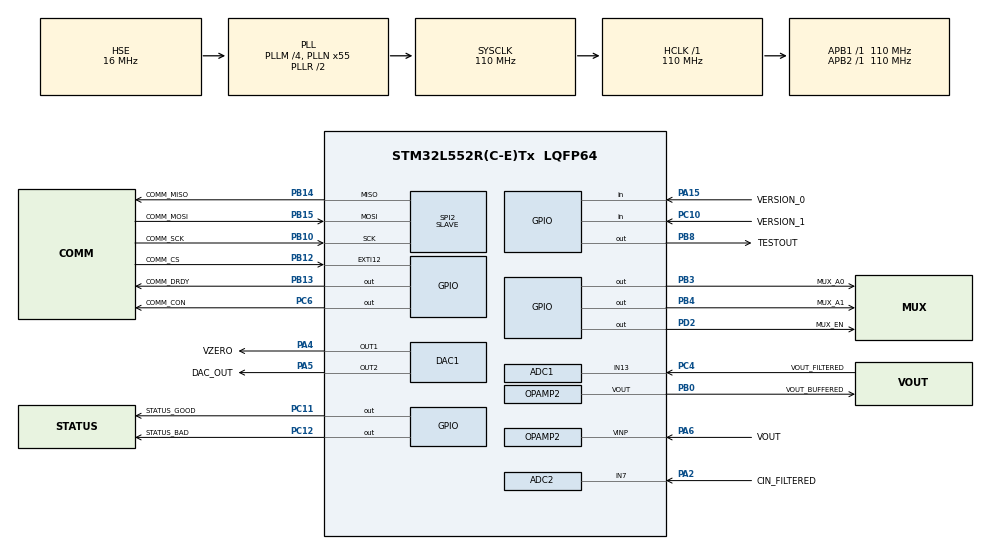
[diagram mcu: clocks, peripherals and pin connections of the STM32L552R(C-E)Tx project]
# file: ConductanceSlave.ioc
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ADC1.Channel-2\#ChannelRegularConversion=ADC_CHANNEL_13
ADC1.ClockPrescaler=ADC_CLOCK_SYNC_PCLK_DIV2
ADC1.ExternalTrigConv=ADC_EXTERNALTRIG_T1_TRGO
ADC1.NbrOfConversion=1
ADC1.NbrOfConversionFlag=1
ADC1.OffsetNumber-2\#ChannelRegularConversion=ADC_OFFSET_NONE
ADC1.OversamplingMode=ENABLE
ADC1.Rank-2\#ChannelRegularConversion=1
ADC1.Ratio=ADC_OVERSAMPLING_RATIO_256
ADC1.RightBitShift=ADC_RIGHTBITSHIFT_4
ADC1.SamplingTime-2\#ChannelRegularConversion=ADC_SAMPLETIME_6CYCLES_5
ADC1.master=1
ADC2.Channel-4\#ChannelRegularConversion=ADC_CHANNEL_7
ADC2.ClockPrescaler=ADC_CLOCK_SYNC_PCLK_DIV2
ADC2.ExternalTrigConv=ADC_EXTERNALTRIG_T1_TRGO
ADC2.NbrOfConversionFlag=1
ADC2.OffsetNumber-4\#ChannelRegularConversion=ADC_OFFSET_NONE
ADC2.OversamplingMode=ENABLE
ADC2.Rank-4\#ChannelRegularConversion=1
ADC2.Ratio=ADC_OVERSAMPLING_RATIO_256
ADC2.RightBitShift=ADC_RIGHTBITSHIFT_4
ADC2.SamplingTime-4\#ChannelRegularConversion=ADC_SAMPLETIME_6CYCLES_5
DAC1.DAC_Channel-DAC_OUT2=DAC_CHANNEL_2
DAC1.DAC_OutputBuffer-DAC_OUT1=DAC_OUTPUTBUFFER_DISABLE
DAC1.DAC_Trigger-DAC_OUT1=DAC_TRIGGER_NONE
Dma.Request0=SPI2_RX
Dma.SPI2_RX.0.Channel_PRIV_NPRIV=DMA_CHANNEL_NPRIV_DISABLE
Dma.SPI2_RX.0.Direction=DMA_PERIPH_TO_MEMORY
Dma.SPI2_RX.0.EventEnable=DISABLE
Dma.SPI2_RX.0.Instance=DMA2_Channel1
Dma.SPI2_RX.0.MemDataAlignment=DMA_MDATAALIGN_HALFWORD
Dma.SPI2_RX.0.MemInc=DMA_MINC_ENABLE
Dma.SPI2_RX.0.Mode=DMA_NORMAL
Dma.SPI2_RX.0.PeriphDataAlignment=DMA_PDATAALIGN_HALFWORD
Dma.SPI2_RX.0.PeriphInc=DMA_PINC_DISABLE
Dma.SPI2_RX.0.Polarity=HAL_DMAMUX_REQ_GEN_RISING
Dma.SPI2_RX.0.Priority=DMA_PRIORITY_HIGH
Dma.SPI2_RX.0.RequestNumber=1
Dma.SPI2_RX.0.SignalID=NONE
Dma.SPI2_RX.0.SyncEnable=DISABLE
Dma.SPI2_RX.0.SyncPolarity=HAL_DMAMUX_SYNC_NO_EVENT
Dma.SPI2_RX.0.SyncRequestNumber=1
Dma.SPI2_RX.0.SyncSignalID=NONE
Mcu.Family=STM32L5
Mcu.Name=STM32L552R(C-E)Tx
Mcu.Package=LQFP64
NVIC.DMA2_Channel1_IRQn=true\:0\:0\:false\:false\:true\:false\:true\:true
NVIC.EXTI12_IRQn=true\:1\:0\:true\:false\:true\:true\:true\:true
NVIC.PriorityGroup=NVIC_PRIORITYGROUP_3
OPAMP2.PowerSupplyRange=OPAMP_POWERSUPPLY_HIGH
PA13\ (JTMS/SWDIO).Mode=Serial_Wire
PA13\ (JTMS/SWDIO).Signal=DEBUG_JTMS-SWDIO
PA14\ (JTCK/SWCLK).Mode=Serial_Wire
PA14\ (JTCK/SWCLK).Signal=DEBUG_JTCK-SWCLK
PA15\ (JTDI).GPIO_Label=VERSION_0
PA15\ (JTDI).GPIO_PuPd=GPIO_PULLDOWN
PA15\ (JTDI).Signal=GPIO_Input
PA2.GPIO_Label=CIN_FILTERED
PA2.Signal=ADCx_IN7
PA4.GPIO_Label=VZERO
PA4.Signal=COMP_DAC11_group
PA5.GPIO_Label=DAC_OUT
PA5.Signal=COMP_DAC12_group
PA6.GPIO_Label=VOUT
PA6.Mode=Follower
PA6.Signal=OPAMP2_VINP
PB0.GPIO_Label=VOUT_BUFFERED
PB0.Mode=Follower
PB0.Signal=OPAMP2_VOUT
PB10.GPIO_Label=COMM_SCK
PB10.GPIO_Speed=GPIO_SPEED_FREQ_VERY_HIGH
PB10.Mode=Full_Duplex_Slave
PB10.Signal=SPI2_SCK
PB12.GPIO_Label=COMM_CS
PB12.GPIO_ModeDefaultEXTI=GPIO_MODE_IT_RISING_FALLING
PB12.GPIO_PuPd=GPIO_PULLUP
PB12.Signal=GPXTI12
PB13.GPIO_Label=COMM_DRDY
PB13.GPIO_ModeDefaultOutputPP=GPIO_MODE_OUTPUT_OD
PB13.GPIO_PuPd=GPIO_NOPULL
PB13.PinState=GPIO_PIN_SET
PB13.Signal=GPIO_Output
PB14.GPIO_Label=COMM_MISO
PB14.GPIO_Speed=GPIO_SPEED_FREQ_VERY_HIGH
PB14.Mode=Full_Duplex_Slave
PB14.Signal=SPI2_MISO
PB15.GPIO_Label=COMM_MOSI
PB15.GPIO_Speed=GPIO_SPEED_FREQ_VERY_HIGH
PB15.Mode=Full_Duplex_Slave
PB15.Signal=SPI2_MOSI
PB3\ (JTDO/TRACESWO).GPIO_Label=MUX_A0
PB3\ (JTDO/TRACESWO).Signal=GPIO_Output
PB4\ (NJTRST).GPIO_Label=MUX_A1
PB4\ (NJTRST).GPIO_ModeDefaultOutputPP=GPIO_MODE_OUTPUT_PP
PB4\ (NJTRST).GPIO_PuPd=GPIO_NOPULL
PB4\ (NJTRST).PinState=GPIO_PIN_RESET
PB4\ (NJTRST).Signal=GPIO_Output
PB8.GPIO_Label=TESTOUT
PB8.Signal=GPIO_Output
PC10.GPIO_Label=VERSION_1
PC10.GPIO_PuPd=GPIO_PULLDOWN
PC10.Signal=GPIO_Input
PC11.GPIO_Label=STATUS_GOOD
PC11.GPIO_ModeDefaultOutputPP=GPIO_MODE_OUTPUT_OD
PC11.GPIO_PuPd=GPIO_NOPULL
PC11.PinState=GPIO_PIN_SET
PC11.Signal=GPIO_Output
PC12.GPIO_Label=STATUS_BAD
PC12.GPIO_ModeDefaultOutputPP=GPIO_MODE_OUTPUT_OD
PC12.GPIO_PuPd=GPIO_NOPULL
PC12.PinState=GPIO_PIN_SET
PC12.Signal=GPIO_Output
PC4.GPIO_Label=VOUT_FILTERED
PC4.Signal=ADCx_IN13
PC6.GPIO_Label=COMM_CON
PC6.GPIO_ModeDefaultOutputPP=GPIO_MODE_OUTPUT_OD
PC6.GPIO_PuPd=GPIO_NOPULL
PC6.PinState=GPIO_PIN_SET
PC6.Signal=GPIO_Output
PD2.GPIO_Label=MUX_EN
PD2.Signal=GPIO_Output
PH0-OSC_IN\ (PH0).Mode=HSE-External-Clock-Source
PH0-OSC_IN\ (PH0).Signal=RCC_OSC_IN
ProjectManager.HeapSize=0x200
ProjectManager.StackSize=0x400
ProjectManager.TargetToolchain=STM32CubeIDE
RCC.ADCCLockSelection=RCC_ADCCLKSOURCE_SYSCLK
RCC.ADCFreq_Value=110000000
RCC.AHBFreq_Value=110000000
RCC.APB1Freq_Value=110000000
RCC.APB1TimFreq_Value=110000000
RCC.APB2Freq_Value=110000000
RCC.APB2TimFreq_Value=110000000
RCC.CortexFreq_Value=110000000
RCC.HCLKFreq_Value=110000000
RCC.HSE_VALUE=16000000
RCC.HSI48_VALUE=48000000
RCC.HSI_VALUE=16000000
RCC.LSE_VALUE=32768
RCC.MSI_VALUE=4000000
RCC.PLLM=4
RCC.PLLN=55
RCC.PLLSAI1N=16
RCC.PLLSourceVirtual=RCC_PLLSOURCE_HSE
RCC.SYSCLKFreq_VALUE=110000000
RCC.SYSCLKSource=RCC_SYSCLKSOURCE_PLLCLK
RCC.USBFreq_Value=32000000
RCC.VCOOutputFreq_Value=220000000
SH.ADCx_IN13.0=ADC1_IN13,IN13-Single-Ended
SH.ADCx_IN7.0=ADC2_IN7,IN7-Single-Ended
SH.COMP_DAC11_group.0=DAC1_OUT1,DAC_OUT1
SH.COMP_DAC12_group.0=DAC1_OUT2,DAC_OUT2
SPI2.CLKPolarity=SPI_POLARITY_LOW
SPI2.CRCCalculation=SPI_CRCCALCULATION_ENABLE
SPI2.CRCLength=SPI_CRC_LENGTH_16BIT
SPI2.DataSize=SPI_DATASIZE_16BIT
SPI2.Direction=SPI_DIRECTION_2LINES
SPI2.Mode=SPI_MODE_SLAVE
SPI2.VirtualType=VM_SLAVE
TIM1.Prescaler=109
TIM1.TIM_MasterOutputTrigger=TIM_TRGO_ENABLE
VP_ICACHE_VS_ICACHE.Mode=DefaultMode
VP_PWR_VS_DBSignals.Mode=DisableDeadBatterySignals
VP_PWR_VS_SECSignals.Mode=Security/Privilege
VP_TIM1_VS_ClockSourceINT.Mode=Internal
board=custom

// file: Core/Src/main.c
/* USER CODE BEGIN Header */
/**
  ******************************************************************************
  * @file           : main.c
  * @brief          : Main program body
  ******************************************************************************
  * @attention
  *
  * <h2><center>&copy; Copyright (c) 2021 STMicroelectronics.
  * All rights reserved.</center></h2>
  *
  * This software component is licensed by ST under BSD 3-Clause license,
  * the "License"; You may not use this file except in compliance with the
  * License. You may obtain a copy of the License at:
  *                        opensource.org/licenses/BSD-3-Clause
  *
  ******************************************************************************
  */
/* USER CODE END Header */
#include "main.h"

/* USER CODE BEGIN Includes */
#include "usermain.h"
/* USER CODE END Includes */

ADC_HandleTypeDef hadc1;
ADC_HandleTypeDef hadc2;

DAC_HandleTypeDef hdac1;

OPAMP_HandleTypeDef hopamp2;

SPI_HandleTypeDef hspi2;
DMA_HandleTypeDef hdma_spi2_rx;

TIM_HandleTypeDef htim1;

void SystemClock_Config(void);
static void MX_GPIO_Init(void);
static void MX_DMA_Init(void);
static void MX_ICACHE_Init(void);
static void MX_TIM1_Init(void);
static void MX_ADC1_Init(void);
static void MX_ADC2_Init(void);
static void MX_DAC1_Init(void);
static void MX_SPI2_Init(void);
static void MX_OPAMP2_Init(void);

int main(void)
{

  /* MCU Configuration--------------------------------------------------------*/

  /* Reset of all peripherals, Initializes the Flash interface and the Systick. */
  HAL_Init();

  /* Configure the system clock */
  SystemClock_Config();

  /* Initialize all configured peripherals */
  MX_GPIO_Init();
  MX_DMA_Init();
  MX_ICACHE_Init();
  MX_TIM1_Init();
  MX_ADC1_Init();
  MX_ADC2_Init();
  MX_DAC1_Init();
  MX_SPI2_Init();
  MX_OPAMP2_Init();
  /* USER CODE BEGIN 2 */
  user_main();
  /* USER CODE END 2 */

  /* Infinite loop */
  while (1)
  {

  }
}

void SystemClock_Config(void)
{
  RCC_OscInitTypeDef RCC_OscInitStruct = {0};
  RCC_ClkInitTypeDef RCC_ClkInitStruct = {0};

  /** Configure the main internal regulator output voltage
  */
  if (HAL_PWREx_ControlVoltageScaling(PWR_REGULATOR_VOLTAGE_SCALE0) != HAL_OK)
  {
    Error_Handler();
  }

  /** Initializes the RCC Oscillators according to the specified parameters
  * in the RCC_OscInitTypeDef structure.
  */
  RCC_OscInitStruct.OscillatorType = RCC_OSCILLATORTYPE_HSE;
  RCC_OscInitStruct.HSEState = RCC_HSE_BYPASS;
  RCC_OscInitStruct.PLL.PLLState = RCC_PLL_ON;
  RCC_OscInitStruct.PLL.PLLSource = RCC_PLLSOURCE_HSE;
  RCC_OscInitStruct.PLL.PLLM = 4;
  RCC_OscInitStruct.PLL.PLLN = 55;
  RCC_OscInitStruct.PLL.PLLP = RCC_PLLP_DIV7;
  RCC_OscInitStruct.PLL.PLLQ = RCC_PLLQ_DIV2;
  RCC_OscInitStruct.PLL.PLLR = RCC_PLLR_DIV2;
  if (HAL_RCC_OscConfig(&RCC_OscInitStruct) != HAL_OK)
  {
    Error_Handler();
  }

  /** Initializes the CPU, AHB and APB buses clocks
  */
  RCC_ClkInitStruct.ClockType = RCC_CLOCKTYPE_HCLK|RCC_CLOCKTYPE_SYSCLK
                              |RCC_CLOCKTYPE_PCLK1|RCC_CLOCKTYPE_PCLK2;
  RCC_ClkInitStruct.SYSCLKSource = RCC_SYSCLKSOURCE_PLLCLK;
  RCC_ClkInitStruct.AHBCLKDivider = RCC_SYSCLK_DIV1;
  RCC_ClkInitStruct.APB1CLKDivider = RCC_HCLK_DIV1;
  RCC_ClkInitStruct.APB2CLKDivider = RCC_HCLK_DIV1;

  if (HAL_RCC_ClockConfig(&RCC_ClkInitStruct, FLASH_LATENCY_5) != HAL_OK)
  {
    Error_Handler();
  }
}

static void MX_ADC1_Init(void)
{

  ADC_MultiModeTypeDef multimode = {0};
  ADC_ChannelConfTypeDef sConfig = {0};

  /** Common config
  */
  hadc1.Instance = ADC1;
  hadc1.Init.ClockPrescaler = ADC_CLOCK_SYNC_PCLK_DIV2;
  hadc1.Init.Resolution = ADC_RESOLUTION_12B;
  hadc1.Init.DataAlign = ADC_DATAALIGN_RIGHT;
  hadc1.Init.ScanConvMode = ADC_SCAN_DISABLE;
  hadc1.Init.EOCSelection = ADC_EOC_SINGLE_CONV;
  hadc1.Init.LowPowerAutoWait = DISABLE;
  hadc1.Init.ContinuousConvMode = DISABLE;
  hadc1.Init.NbrOfConversion = 1;
  hadc1.Init.DiscontinuousConvMode = DISABLE;
  hadc1.Init.ExternalTrigConv = ADC_EXTERNALTRIG_T1_TRGO;
  hadc1.Init.ExternalTrigConvEdge = ADC_EXTERNALTRIGCONVEDGE_RISING;
  hadc1.Init.DMAContinuousRequests = DISABLE;
  hadc1.Init.Overrun = ADC_OVR_DATA_PRESERVED;
  hadc1.Init.OversamplingMode = ENABLE;
  hadc1.Init.Oversampling.Ratio = ADC_OVERSAMPLING_RATIO_256;
  hadc1.Init.Oversampling.RightBitShift = ADC_RIGHTBITSHIFT_4;
  hadc1.Init.Oversampling.TriggeredMode = ADC_TRIGGEREDMODE_SINGLE_TRIGGER;
  hadc1.Init.Oversampling.OversamplingStopReset = ADC_REGOVERSAMPLING_CONTINUED_MODE;
  if (HAL_ADC_Init(&hadc1) != HAL_OK)
  {
    Error_Handler();
  }

  /** Configure the ADC multi-mode
  */
  multimode.Mode = ADC_MODE_INDEPENDENT;
  if (HAL_ADCEx_MultiModeConfigChannel(&hadc1, &multimode) != HAL_OK)
  {
    Error_Handler();
  }

  /** Configure Regular Channel
  */
  sConfig.Channel = ADC_CHANNEL_13;
  sConfig.Rank = ADC_REGULAR_RANK_1;
  sConfig.SamplingTime = ADC_SAMPLETIME_6CYCLES_5;
  sConfig.SingleDiff = ADC_SINGLE_ENDED;
  sConfig.OffsetNumber = ADC_OFFSET_NONE;
  sConfig.Offset = 0;
  if (HAL_ADC_ConfigChannel(&hadc1, &sConfig) != HAL_OK)
  {
    Error_Handler();
  }

}

static void MX_ADC2_Init(void)
{

  ADC_ChannelConfTypeDef sConfig = {0};

  /** Common config
  */
  hadc2.Instance = ADC2;
  hadc2.Init.ClockPrescaler = ADC_CLOCK_SYNC_PCLK_DIV2;
  hadc2.Init.Resolution = ADC_RESOLUTION_12B;
  hadc2.Init.DataAlign = ADC_DATAALIGN_RIGHT;
  hadc2.Init.ScanConvMode = ADC_SCAN_DISABLE;
  hadc2.Init.EOCSelection = ADC_EOC_SINGLE_CONV;
  hadc2.Init.LowPowerAutoWait = DISABLE;
  hadc2.Init.ContinuousConvMode = DISABLE;
  hadc2.Init.NbrOfConversion = 1;
  hadc2.Init.DiscontinuousConvMode = DISABLE;
  hadc2.Init.ExternalTrigConv = ADC_EXTERNALTRIG_T1_TRGO;
  hadc2.Init.ExternalTrigConvEdge = ADC_EXTERNALTRIGCONVEDGE_RISING;
  hadc2.Init.DMAContinuousRequests = DISABLE;
  hadc2.Init.Overrun = ADC_OVR_DATA_PRESERVED;
  hadc2.Init.OversamplingMode = ENABLE;
  hadc2.Init.Oversampling.Ratio = ADC_OVERSAMPLING_RATIO_256;
  hadc2.Init.Oversampling.RightBitShift = ADC_RIGHTBITSHIFT_4;
  hadc2.Init.Oversampling.TriggeredMode = ADC_TRIGGEREDMODE_SINGLE_TRIGGER;
  hadc2.Init.Oversampling.OversamplingStopReset = ADC_REGOVERSAMPLING_CONTINUED_MODE;
  if (HAL_ADC_Init(&hadc2) != HAL_OK)
  {
    Error_Handler();
  }

  /** Configure Regular Channel
  */
  sConfig.Channel = ADC_CHANNEL_7;
  sConfig.Rank = ADC_REGULAR_RANK_1;
  sConfig.SamplingTime = ADC_SAMPLETIME_6CYCLES_5;
  sConfig.SingleDiff = ADC_SINGLE_ENDED;
  sConfig.OffsetNumber = ADC_OFFSET_NONE;
  sConfig.Offset = 0;
  if (HAL_ADC_ConfigChannel(&hadc2, &sConfig) != HAL_OK)
  {
    Error_Handler();
  }

}

static void MX_DAC1_Init(void)
{

  DAC_ChannelConfTypeDef sConfig = {0};

  /** DAC Initialization
  */
  hdac1.Instance = DAC1;
  if (HAL_DAC_Init(&hdac1) != HAL_OK)
  {
    Error_Handler();
  }

  /** DAC channel OUT1 config
  */
  sConfig.DAC_SampleAndHold = DAC_SAMPLEANDHOLD_DISABLE;
  sConfig.DAC_Trigger = DAC_TRIGGER_NONE;
  sConfig.DAC_HighFrequency = DAC_HIGH_FREQUENCY_INTERFACE_MODE_ABOVE_80MHZ;
  sConfig.DAC_OutputBuffer = DAC_OUTPUTBUFFER_DISABLE;
  sConfig.DAC_ConnectOnChipPeripheral = DAC_CHIPCONNECT_DISABLE;
  sConfig.DAC_UserTrimming = DAC_TRIMMING_FACTORY;
  if (HAL_DAC_ConfigChannel(&hdac1, &sConfig, DAC_CHANNEL_1) != HAL_OK)
  {
    Error_Handler();
  }

  /** DAC channel OUT2 config
  */
  sConfig.DAC_OutputBuffer = DAC_OUTPUTBUFFER_ENABLE;
  if (HAL_DAC_ConfigChannel(&hdac1, &sConfig, DAC_CHANNEL_2) != HAL_OK)
  {
    Error_Handler();
  }

}

static void MX_ICACHE_Init(void)
{

  /** Enable instruction cache (default 2-ways set associative cache)
  */
  if (HAL_ICACHE_Enable() != HAL_OK)
  {
    Error_Handler();
  }

}

static void MX_OPAMP2_Init(void)
{

  hopamp2.Instance = OPAMP2;
  hopamp2.Init.PowerSupplyRange = OPAMP_POWERSUPPLY_HIGH;
  hopamp2.Init.Mode = OPAMP_FOLLOWER_MODE;
  hopamp2.Init.NonInvertingInput = OPAMP_NONINVERTINGINPUT_IO0;
  hopamp2.Init.PowerMode = OPAMP_POWERMODE_NORMALPOWER;
  hopamp2.Init.UserTrimming = OPAMP_TRIMMING_FACTORY;
  if (HAL_OPAMP_Init(&hopamp2) != HAL_OK)
  {
    Error_Handler();
  }

}

static void MX_SPI2_Init(void)
{

  /* SPI2 parameter configuration*/
  hspi2.Instance = SPI2;
  hspi2.Init.Mode = SPI_MODE_SLAVE;
  hspi2.Init.Direction = SPI_DIRECTION_2LINES;
  hspi2.Init.DataSize = SPI_DATASIZE_16BIT;
  hspi2.Init.CLKPolarity = SPI_POLARITY_LOW;
  hspi2.Init.CLKPhase = SPI_PHASE_1EDGE;
  hspi2.Init.NSS = SPI_NSS_SOFT;
  hspi2.Init.FirstBit = SPI_FIRSTBIT_MSB;
  hspi2.Init.TIMode = SPI_TIMODE_DISABLE;
  hspi2.Init.CRCCalculation = SPI_CRCCALCULATION_ENABLE;
  hspi2.Init.CRCPolynomial = 7;
  hspi2.Init.CRCLength = SPI_CRC_LENGTH_16BIT;
  hspi2.Init.NSSPMode = SPI_NSS_PULSE_DISABLE;
  if (HAL_SPI_Init(&hspi2) != HAL_OK)
  {
    Error_Handler();
  }

}

static void MX_TIM1_Init(void)
{

  TIM_ClockConfigTypeDef sClockSourceConfig = {0};
  TIM_MasterConfigTypeDef sMasterConfig = {0};

  htim1.Instance = TIM1;
  htim1.Init.Prescaler = 109;
  htim1.Init.CounterMode = TIM_COUNTERMODE_UP;
  htim1.Init.Period = 65535;
  htim1.Init.ClockDivision = TIM_CLOCKDIVISION_DIV1;
  htim1.Init.RepetitionCounter = 0;
  htim1.Init.AutoReloadPreload = TIM_AUTORELOAD_PRELOAD_DISABLE;
  if (HAL_TIM_Base_Init(&htim1) != HAL_OK)
  {
    Error_Handler();
  }
  sClockSourceConfig.ClockSource = TIM_CLOCKSOURCE_INTERNAL;
  if (HAL_TIM_ConfigClockSource(&htim1, &sClockSourceConfig) != HAL_OK)
  {
    Error_Handler();
  }
  sMasterConfig.MasterOutputTrigger = TIM_TRGO_ENABLE;
  sMasterConfig.MasterOutputTrigger2 = TIM_TRGO2_RESET;
  sMasterConfig.MasterSlaveMode = TIM_MASTERSLAVEMODE_DISABLE;
  if (HAL_TIMEx_MasterConfigSynchronization(&htim1, &sMasterConfig) != HAL_OK)
  {
    Error_Handler();
  }

}

static void MX_DMA_Init(void)
{

  /* DMA controller clock enable */
  __HAL_RCC_DMAMUX1_CLK_ENABLE();
  __HAL_RCC_DMA2_CLK_ENABLE();

  /* DMA interrupt init */
  /* DMA2_Channel1_IRQn interrupt configuration */
  HAL_NVIC_SetPriority(DMA2_Channel1_IRQn, 0, 0);
  HAL_NVIC_EnableIRQ(DMA2_Channel1_IRQn);

}

static void MX_GPIO_Init(void)
{
  GPIO_InitTypeDef GPIO_InitStruct = {0};

  /* GPIO Ports Clock Enable */
  __HAL_RCC_GPIOC_CLK_ENABLE();
  __HAL_RCC_GPIOH_CLK_ENABLE();
  __HAL_RCC_GPIOA_CLK_ENABLE();
  __HAL_RCC_GPIOB_CLK_ENABLE();
  __HAL_RCC_GPIOD_CLK_ENABLE();

  /*Configure GPIO pin Output Level */
  HAL_GPIO_WritePin(COMM_DRDY_GPIO_Port, COMM_DRDY_Pin, GPIO_PIN_SET);

  /*Configure GPIO pin Output Level */
  HAL_GPIO_WritePin(GPIOC, COMM_CON_Pin|STATUS_GOOD_Pin|STATUS_BAD_Pin, GPIO_PIN_SET);

  /*Configure GPIO pin Output Level */
  HAL_GPIO_WritePin(MUX_EN_GPIO_Port, MUX_EN_Pin, GPIO_PIN_RESET);

  /*Configure GPIO pin Output Level */
  HAL_GPIO_WritePin(GPIOB, MUX_A0_Pin|MUX_A1_Pin|TESTOUT_Pin, GPIO_PIN_RESET);

  /*Configure GPIO pins : PC13 PC14 PC15 PC0
                           PC1 PC2 PC3 PC5
                           PC7 PC8 PC9 */
  GPIO_InitStruct.Pin = GPIO_PIN_13|GPIO_PIN_14|GPIO_PIN_15|GPIO_PIN_0
                          |GPIO_PIN_1|GPIO_PIN_2|GPIO_PIN_3|GPIO_PIN_5
                          |GPIO_PIN_7|GPIO_PIN_8|GPIO_PIN_9;
  GPIO_InitStruct.Mode = GPIO_MODE_ANALOG;
  GPIO_InitStruct.Pull = GPIO_NOPULL;
  HAL_GPIO_Init(GPIOC, &GPIO_InitStruct);

  /*Configure GPIO pin : PH1 */
  GPIO_InitStruct.Pin = GPIO_PIN_1;
  GPIO_InitStruct.Mode = GPIO_MODE_ANALOG;
  GPIO_InitStruct.Pull = GPIO_NOPULL;
  HAL_GPIO_Init(GPIOH, &GPIO_InitStruct);

  /*Configure GPIO pins : PA0 PA1 PA3 PA7
                           PA8 PA9 PA10 PA11
                           PA12 */
  GPIO_InitStruct.Pin = GPIO_PIN_0|GPIO_PIN_1|GPIO_PIN_3|GPIO_PIN_7
                          |GPIO_PIN_8|GPIO_PIN_9|GPIO_PIN_10|GPIO_PIN_11
                          |GPIO_PIN_12;
  GPIO_InitStruct.Mode = GPIO_MODE_ANALOG;
  GPIO_InitStruct.Pull = GPIO_NOPULL;
  HAL_GPIO_Init(GPIOA, &GPIO_InitStruct);

  /*Configure GPIO pins : PB1 PB2 PB11 PB5
                           PB6 PB7 PB9 */
  GPIO_InitStruct.Pin = GPIO_PIN_1|GPIO_PIN_2|GPIO_PIN_11|GPIO_PIN_5
                          |GPIO_PIN_6|GPIO_PIN_7|GPIO_PIN_9;
  GPIO_InitStruct.Mode = GPIO_MODE_ANALOG;
  GPIO_InitStruct.Pull = GPIO_NOPULL;
  HAL_GPIO_Init(GPIOB, &GPIO_InitStruct);

  /*Configure GPIO pin : COMM_CS_Pin */
  GPIO_InitStruct.Pin = COMM_CS_Pin;
  GPIO_InitStruct.Mode = GPIO_MODE_IT_RISING_FALLING;
  GPIO_InitStruct.Pull = GPIO_PULLUP;
  HAL_GPIO_Init(COMM_CS_GPIO_Port, &GPIO_InitStruct);

  /*Configure GPIO pin : COMM_DRDY_Pin */
  GPIO_InitStruct.Pin = COMM_DRDY_Pin;
  GPIO_InitStruct.Mode = GPIO_MODE_OUTPUT_OD;
  GPIO_InitStruct.Pull = GPIO_NOPULL;
  GPIO_InitStruct.Speed = GPIO_SPEED_FREQ_LOW;
  HAL_GPIO_Init(COMM_DRDY_GPIO_Port, &GPIO_InitStruct);

  /*Configure GPIO pins : COMM_CON_Pin STATUS_GOOD_Pin STATUS_BAD_Pin */
  GPIO_InitStruct.Pin = COMM_CON_Pin|STATUS_GOOD_Pin|STATUS_BAD_Pin;
  GPIO_InitStruct.Mode = GPIO_MODE_OUTPUT_OD;
  GPIO_InitStruct.Pull = GPIO_NOPULL;
  GPIO_InitStruct.Speed = GPIO_SPEED_FREQ_LOW;
  HAL_GPIO_Init(GPIOC, &GPIO_InitStruct);

  /*Configure GPIO pin : VERSION_0_Pin */
  GPIO_InitStruct.Pin = VERSION_0_Pin;
  GPIO_InitStruct.Mode = GPIO_MODE_INPUT;
  GPIO_InitStruct.Pull = GPIO_PULLDOWN;
  HAL_GPIO_Init(VERSION_0_GPIO_Port, &GPIO_InitStruct);

  /*Configure GPIO pin : VERSION_1_Pin */
  GPIO_InitStruct.Pin = VERSION_1_Pin;
  GPIO_InitStruct.Mode = GPIO_MODE_INPUT;
  GPIO_InitStruct.Pull = GPIO_PULLDOWN;
  HAL_GPIO_Init(VERSION_1_GPIO_Port, &GPIO_InitStruct);

  /*Configure GPIO pin : MUX_EN_Pin */
  GPIO_InitStruct.Pin = MUX_EN_Pin;
  GPIO_InitStruct.Mode = GPIO_MODE_OUTPUT_PP;
  GPIO_InitStruct.Pull = GPIO_NOPULL;
  GPIO_InitStruct.Speed = GPIO_SPEED_FREQ_LOW;
  HAL_GPIO_Init(MUX_EN_GPIO_Port, &GPIO_InitStruct);

  /*Configure GPIO pins : MUX_A0_Pin MUX_A1_Pin TESTOUT_Pin */
  GPIO_InitStruct.Pin = MUX_A0_Pin|MUX_A1_Pin|TESTOUT_Pin;
  GPIO_InitStruct.Mode = GPIO_MODE_OUTPUT_PP;
  GPIO_InitStruct.Pull = GPIO_NOPULL;
  GPIO_InitStruct.Speed = GPIO_SPEED_FREQ_LOW;
  HAL_GPIO_Init(GPIOB, &GPIO_InitStruct);

  /* EXTI interrupt init*/
  HAL_NVIC_SetPriority(EXTI12_IRQn, 1, 0);
  HAL_NVIC_EnableIRQ(EXTI12_IRQn);

}

void Error_Handler(void)
{
  __disable_irq();
  while (1)
  {
  }
}
